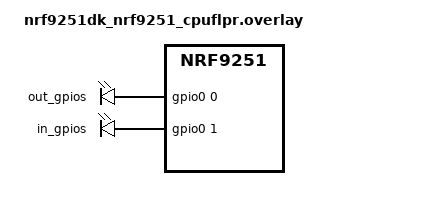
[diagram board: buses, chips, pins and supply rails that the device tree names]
/*
 * Copyright (c) 2026 Nordic Semiconductor ASA
 *
 * SPDX-License-Identifier: LicenseRef-Nordic-5-Clause
 */

/ {
	/* Test requirements:
	 * out-gpios[0] wire connected with in-gpios[0],
	 * out-gpios[1] wire connected with in-gpios[1],
	 * etc.
	 * Output-input GPIO pair must have identical active level flag.
	 */
	test_gpios {
		compatible = "gpio-leds";

		out_gpios: out_gpios {
			gpios = <&gpio0 0 GPIO_ACTIVE_HIGH>, <&gpio1 0 GPIO_ACTIVE_HIGH>,
				<&gpio1 2 GPIO_ACTIVE_HIGH>, <&gpio2 1 GPIO_ACTIVE_HIGH>,
				<&gpio2 3 GPIO_ACTIVE_HIGH>;
		};

		in_gpios: in_gpios {
			gpios = <&gpio0 1 GPIO_ACTIVE_HIGH>, <&gpio1 1 GPIO_ACTIVE_HIGH>,
				<&gpio1 4 GPIO_ACTIVE_HIGH>, <&gpio2 2 GPIO_ACTIVE_HIGH>,
				<&gpio2 9 GPIO_ACTIVE_HIGH>;
		};
	};
};

&gpiote130 {
	status = "okay";
};

&gpio0 {
	status = "okay";
};

&gpio1 {
	status = "okay";
};

&gpio2 {
	status = "okay";
};
